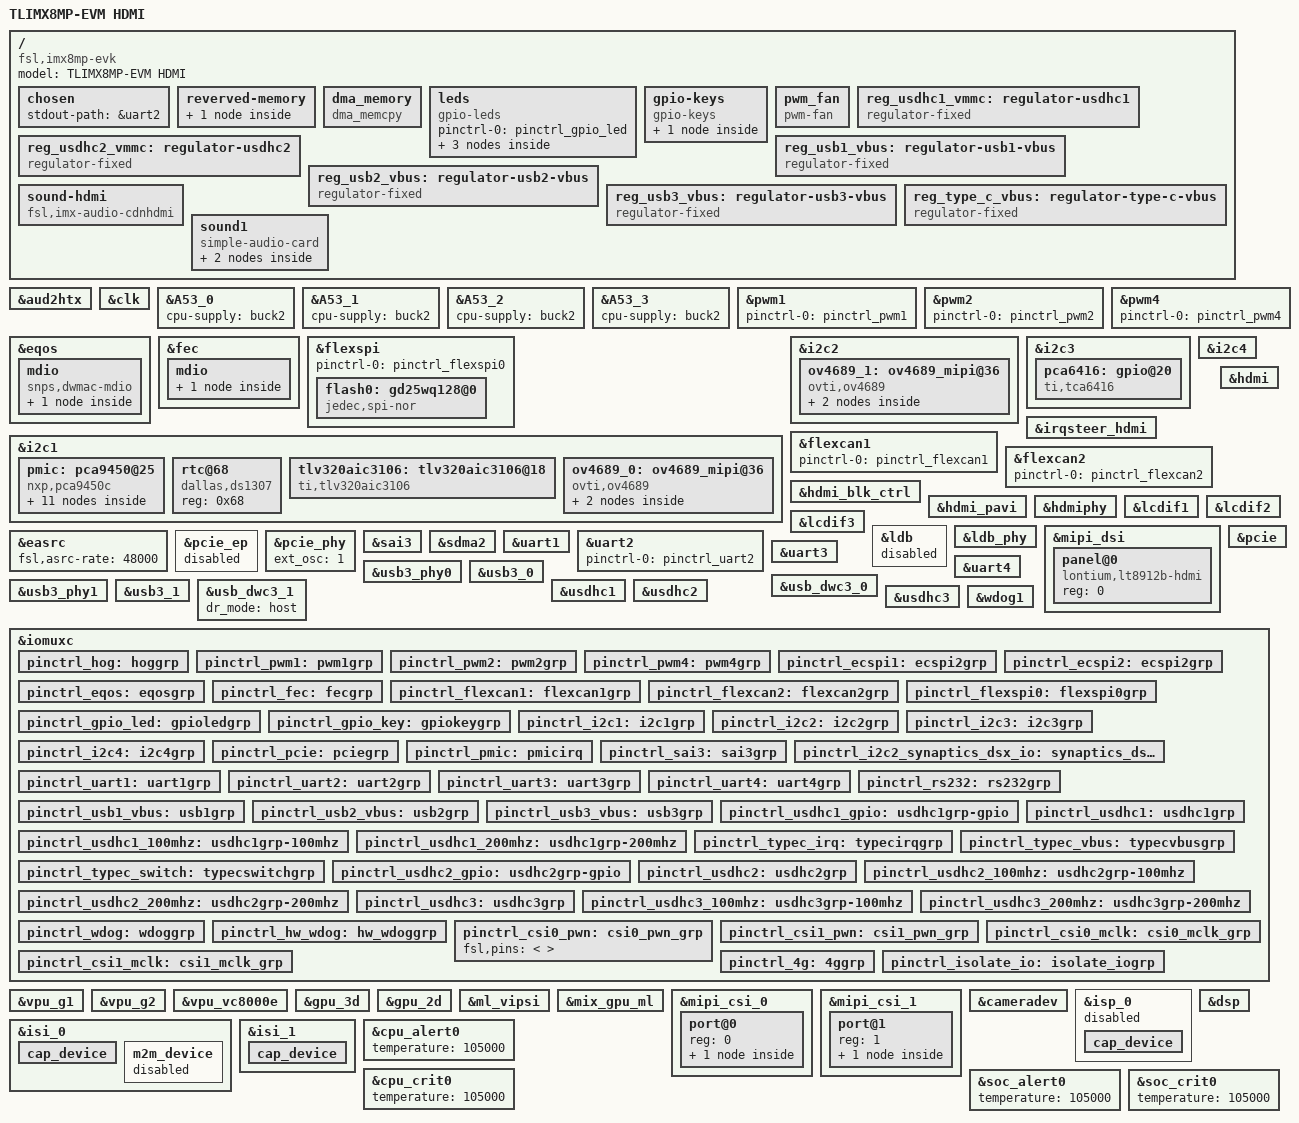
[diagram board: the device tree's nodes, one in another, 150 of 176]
/*
 * Copyright (C) 2015 GuangZhou Tronlong co., LTD - http://www.tronlong.com
 *
 * This program is free software; you can redistribute it and/or modify
 * it under the terms of the GNU General Public License version 2 as
 * published by the Free Software Foundation.
 */

/dts-v1/;

#include <dt-bindings/usb/pd.h>
#include "imx8mp.dtsi"

/{
	model = "TLIMX8MP-EVM HDMI";

	compatible = "fsl,imx8mp-evk", "fsl,imx8mp";

	chosen {
		stdout-path = &uart2;
	};

	reverved-memory {
		#address-cells = <2>;
		#size-cells = <2>;
		ranges;

		rpmsg_reserved: rpmsg@0x55800000 {
			no-map;
			reg = <0 0x55800000 0 0x800000>;
		};
	};
	
	dma_memory {
		status = "okay";
		compatible = "dma_memcpy";
	};

	leds {
		compatible = "gpio-leds";
		pinctrl-names = "default";
		pinctrl-0 = <&pinctrl_gpio_led>;

		led@0 {
			label = "heartbeat";
			gpios = <&gpio3 16 GPIO_ACTIVE_HIGH>;
			linux,default-trigger = "heartbeat";
			default-state = "off";
		};

		led@1 {
			label = "disk";
			gpios = <&gpio1 0 GPIO_ACTIVE_HIGH>;
			linux,default-trigger = "mmc2";
			default-state = "off";
		};

		led@2 {
			label = "user-led0";
			gpios = <&gpio1 5 GPIO_ACTIVE_HIGH>;
			default-state = "on";
		};
	};

	gpio-keys {
		compatible = "gpio-keys";
		#address-cells = <1>;
		#size-cells = <0>;
		autorepeat;

		pinctrl-names = "default";
		pinctrl-0 = <&pinctrl_gpio_key>;

		user_key@0 {
			label = "user-key0";
			gpios = <&gpio1 1 GPIO_ACTIVE_LOW>;
			linux,code = <KEY_PROG1>;
			debounce-interval = <0>;
		};
	};

	pwm_fan: pwm_fan {
		compatible = "pwm-fan";
		cooling-min-state = <0>;
		cooling-max-state = <3>;
		#cooling-cells = <2>;
		pwms = <&pwm4 0 50000 0>;
		cooling-levels = <0 102 170 230>;
	};

	reg_usdhc1_vmmc: regulator-usdhc1 {
		compatible = "regulator-fixed";
		regulator-name = "VSD_3V3";
		regulator-min-microvolt = <3300000>;
		regulator-max-microvolt = <3300000>;
		gpio = <&gpio2 10 GPIO_ACTIVE_HIGH>;
		enable-active-high;
		startup-delay-us = <100>;
		off-on-delay-us = <12000>;
	};

	reg_usdhc2_vmmc: regulator-usdhc2 {
		compatible = "regulator-fixed";
		regulator-name = "VSD_3V3";
		regulator-min-microvolt = <3300000>;
		regulator-max-microvolt = <3300000>;
		gpio = <&gpio2 19 GPIO_ACTIVE_HIGH>;
		enable-active-high;
		startup-delay-us = <100>;
		off-on-delay-us = <12000>;
	};

	reg_usb1_vbus: regulator-usb1-vbus {
		compatible = "regulator-fixed";
		regulator-name = "usb1-vbus";
		pinctrl-names = "default";
		pinctrl-0 = <&pinctrl_usb1_vbus>;
		regulator-min-microvolt = <3300000>;
		regulator-max-microvolt = <3300000>;
		gpio = <&gpio4 28 GPIO_ACTIVE_HIGH>;
		enable-active-high;
		regulator-always-on;
	};

	reg_usb2_vbus: regulator-usb2-vbus {
		compatible = "regulator-fixed";
		regulator-name = "usb2-vbus";
		pinctrl-names = "default";
		pinctrl-0 = <&pinctrl_usb2_vbus>;
		regulator-min-microvolt = <3300000>;
		regulator-max-microvolt = <3300000>;
		gpio = <&gpio1 6 GPIO_ACTIVE_HIGH>;
		enable-active-high;
		regulator-always-on;
	};

	reg_usb3_vbus: regulator-usb3-vbus {
		compatible = "regulator-fixed";
		regulator-name = "usb3-vbus";
		pinctrl-names = "default";
		pinctrl-0 = <&pinctrl_usb3_vbus>;
		regulator-min-microvolt = <3300000>;
		regulator-max-microvolt = <3300000>;
		gpio = <&gpio5 5 GPIO_ACTIVE_HIGH>;
		enable-active-high;
		regulator-always-on;
	};

	reg_type_c_vbus: regulator-type-c-vbus {
		compatible = "regulator-fixed";
		regulator-name = "type-c-vbus";
		pinctrl-names = "default";
		pinctrl-0 = <&pinctrl_typec_vbus>;
		regulator-min-microvolt = <3300000>;
		regulator-max-microvolt = <3300000>;
		gpio = <&gpio4 21 GPIO_ACTIVE_HIGH>;
		enable-active-high;
		regulator-always-on;
	};

	sound-hdmi {
		compatible = "fsl,imx-audio-cdnhdmi";
		model = "audio-hdmi";
		audio-cpu = <&aud2htx>;
		hdmi-out;
		constraint-rate = <44100>,
				<88200>,
				<176400>,
				<32000>,
				<48000>,
				<96000>,
				<192000>;
		status = "okay";
	};


	sound1: sound1 {
		compatible = "simple-audio-card";
		simple-audio-card,name = "TLV320AIC3x-Card";
		simple-audio-card,widgets =
			"Line", "Line In Jack",
			"Line", "Line Out Jack";
		simple-audio-card,routing =
			"LINE1L", "Line In Jack",
			"LINE1R", "Line In Jack",
			"Line Out Jack", "LLOUT",
			"Line Out Jack", "RLOUT";

		simple-audio-card,format = "dsp_b";
		simple-audio-card,bitclock-master = <&sound1_master>;
		simple-audio-card,frame-master = <&sound1_master>;
		simple-audio-card,bitclock-inversion;

		cpudai: simple-audio-card,cpu {
			sound-dai = <&sai3 0>;
		};

		sound1_master: simple-audio-card,codec {
			sound-dai = <&tlv320aic3106>;
			clocks = <&audio_blk_ctrl IMX8MP_CLK_AUDIO_BLK_CTRL_SAI3_MCLK1>;
			system-clock-frequency = <24576000>;
			system-clock-direction-out;
		};
	};

};

&aud2htx {
	status = "okay";
};

&clk {
	init-on-array = <IMX8MP_CLK_HSIO_ROOT IMX8MP_CLK_IPP_DO_CLKO1 IMX8MP_CLK_IPP_DO_CLKO2>;
};

&A53_0 {
	cpu-supply = <&buck2>;
};
&A53_1 {
	cpu-supply = <&buck2>;
};
&A53_2 {
	cpu-supply = <&buck2>;
};
&A53_3 {
	cpu-supply = <&buck2>;
};

&pwm1 {
	pinctrl-names = "default";
	pinctrl-0 = <&pinctrl_pwm1>;
	status = "okay";
};

&pwm2 {
	pinctrl-names = "default";
	pinctrl-0 = <&pinctrl_pwm2>;
	status = "okay";
};

&pwm4 {
	pinctrl-names = "default";
	pinctrl-0 = <&pinctrl_pwm4>;
	status = "okay";
};

/*
&ecspi2 {
	#address-cells = <1>;
	#size-cells = <0>;
	fsl,spi-num-chipselects = <1>;
	pinctrl-names = "default";
	pinctrl-0 = <&pinctrl_ecspi2 &pinctrl_ecspi2_cs>;
	cs-gpios = <&gpio5 13 GPIO_ACTIVE_LOW>;
	status = "okay";

	spidev1: spi@0 {
		reg = <0>;
		compatible = "rohm,dh2228fv";
		spi-max-frequency = <500000>;
	};
};
*/

&eqos {
	pinctrl-names = "default";
	pinctrl-0 = <&pinctrl_eqos>;
	phy-mode = "rgmii-id";
	phy-handle = <&ethphy0>;
	status = "okay";

	phy-reset-gpios = <&gpio4 0 GPIO_ACTIVE_LOW>;
	phy-reset-duration = <50>;
	phy-reset-post-delay = <50>;

	mdio {
		compatible = "snps,dwmac-mdio";
		#address-cells = <1>;
		#size-cells = <0>;

		ethphy0: ethernet-phy@1 {
			compatible = "ethernet-phy-ieee802.3-c22";
			reg = <1>;
			eee-broken-1000t;
			phy-tx-delay = <0x08>;	/* yt8521sh tx delay: 0~0xf, 150ps each step */
			phy-rx-delay = <0x00>;	/* yt8521sh rx delay: 0~0xf, 150ps each step */
		};
	};
};

&fec {
	pinctrl-names = "default";
	pinctrl-0 = <&pinctrl_fec>;
	phy-mode = "rgmii-id";
	phy-handle = <&ethphy1>;
	fsl,magic-packet;
	status = "okay";

	phy-reset-gpios = <&gpio4 24 GPIO_ACTIVE_LOW>;
	phy-reset-duration = <50>;
	phy-reset-post-delay = <50>;

	mdio {
		#address-cells = <1>;
		#size-cells = <0>;

		ethphy1: ethernet-phy@1 {
			compatible = "ethernet-phy-ieee802.3-c22";
			reg = <0>;
			eee-broken-1000t;
			phy-tx-delay = <0x01>;	/* yt8521sh tx delay: 0~0xf, 150ps each step */
			phy-rx-delay = <0x00>;	/* yt8521sh rx delay: 0~0xf, 150ps each step */
		};
	};
};

&flexspi {
	pinctrl-names = "default";
	pinctrl-0 = <&pinctrl_flexspi0>;
	status = "okay";

	flash0: gd25wq128@0 {
		reg = <0>;
		#address-cells = <1>;
		#size-cells = <1>;
		compatible = "jedec,spi-nor";
		spi-max-frequency = <80000000>;
		spi-tx-bus-width = <4>;
		spi-rx-bus-width = <4>;
	};
};

&i2c1 {
	clock-frequency = <100000>;
	pinctrl-names = "default";
	pinctrl-0 = <&pinctrl_i2c1>;
	status = "okay";

	pmic: pca9450@25 {
		reg = <0x25>;
		compatible = "nxp,pca9450c";
		pinctrl-names = "default";
		pinctrl-0 = <&pinctrl_pmic>;
		interrupt-parent = <&gpio1>;
		interrupts = <3 IRQ_TYPE_LEVEL_LOW>;

		regulators {
			buck1: BUCK1 {
                                regulator-name = "BUCK1";
                                regulator-min-microvolt = <600000>;
                                regulator-max-microvolt = <2187500>;
                                regulator-boot-on;
                                regulator-always-on;
                                regulator-ramp-delay = <3125>;
                        };

			buck2: BUCK2 {
                                regulator-name = "BUCK2";
                                regulator-min-microvolt = <600000>;
                                regulator-max-microvolt = <2187500>;
                                regulator-boot-on;
                                regulator-always-on;
                                regulator-ramp-delay = <3125>;
                                nxp,dvs-run-voltage = <950000>;
                                nxp,dvs-standby-voltage = <850000>;
                        };

                        buck4: BUCK4 {
                                regulator-name = "BUCK4";
                                regulator-min-microvolt = <600000>;
                                regulator-max-microvolt = <3400000>;
                                regulator-boot-on;
                                regulator-always-on;
                        };

                        buck5: BUCK5 {
                                regulator-name = "BUCK5";
                                regulator-min-microvolt = <600000>;
                                regulator-max-microvolt = <3400000>;
                                regulator-boot-on;
                                regulator-always-on;
                        };

                        buck6: BUCK6 {
                                regulator-name = "BUCK6";
                                regulator-min-microvolt = <600000>;
                                regulator-max-microvolt = <3400000>;
                                regulator-boot-on;
                                regulator-always-on;
                        };

                        ldo1: LDO1 {
                                regulator-name = "LDO1";
                                regulator-min-microvolt = <1600000>;
                                regulator-max-microvolt = <3300000>;
                                regulator-boot-on;
                                regulator-always-on;
                        };

                        ldo2: LDO2 {
                                regulator-name = "LDO2";
                                regulator-min-microvolt = <800000>;
                                regulator-max-microvolt = <1150000>;
                                regulator-boot-on;
                                regulator-always-on;
                        };

                        ldo3: LDO3 {
                                regulator-name = "LDO3";
                                regulator-min-microvolt = <800000>;
                                regulator-max-microvolt = <3300000>;
                                regulator-boot-on;
                                regulator-always-on;
                        };

                        ldo4: LDO4 {
                                regulator-name = "LDO4";
                                regulator-min-microvolt = <800000>;
                                regulator-max-microvolt = <3300000>;
                                regulator-boot-on;
                                regulator-always-on;
                        };

                        ldo5: LDO5 {
                                regulator-name = "LDO5";
                                regulator-min-microvolt = <1800000>;
                                regulator-max-microvolt = <3300000>;
                                regulator-boot-on;
                                regulator-always-on;
			};
		};
	};

	rtc@68 {
		compatible = "dallas,ds1307";
		reg = <0x68>;
	};

	tlv320aic3106: tlv320aic3106@18 {
		#sound-dai-cells = <0>;
		compatible = "ti,tlv320aic3106";
		reg = <0x18>;
		status = "okay";
		ai3x-micbias-vg = <2>; /* MICBIAS output is powered to 2.0V */
	};

        ov4689_0: ov4689_mipi@36 {
                compatible = "ovti,ov4689";
                reg = <0x36>;
                pinctrl-names = "default";
                pinctrl-0 = <&pinctrl_csi0_pwn>, <&pinctrl_csi0_mclk>;
                clocks = <&clk IMX8MP_CLK_IPP_DO_CLKO2>;
                clock-names = "xclk";
                assigned-clocks = <&clk IMX8MP_CLK_IPP_DO_CLKO2>;
                assigned-clock-parents = <&clk IMX8MP_CLK_24M>;
                assigned-clock-rates = <24000000>;
                csi_id = <0>;
                mclk = <24000000>;
                mclk_source = <0>;
                mipi_csi;
                status = "okay";

                port {
                        ov4689_mipi_0_ep: endpoint {
                                remote-endpoint = <&mipi_csi0_ep>;
				data-lanes = <1 2 3 4>;
                                clock-lanes = <0>;
                        };
                };
        };

};

&i2c2 {
	clock-frequency = <100000>;
	pinctrl-names = "default";
	pinctrl-0 = <&pinctrl_i2c2>;
	status = "okay";

        ov4689_1: ov4689_mipi@36 {
                compatible = "ovti,ov4689";
                reg = <0x36>;
                pinctrl-names = "default";
                pinctrl-0 = <&pinctrl_csi1_pwn>, <&pinctrl_csi1_mclk>;
                clocks = <&clk IMX8MP_CLK_IPP_DO_CLKO2>;
                clock-names = "xclk";
                assigned-clocks = <&clk IMX8MP_CLK_IPP_DO_CLKO2>;
                assigned-clock-parents = <&clk IMX8MP_CLK_24M>;
                assigned-clock-rates = <24000000>;
                csi_id = <1>;
                mclk = <24000000>;
                mclk_source = <0>;
                mipi_csi;
                status = "okay";

                port {
                        ov4689_mipi_1_ep: endpoint {
                                remote-endpoint = <&mipi_csi1_ep>;
                                data-lanes = <1 2 3 4>;
                                clock-lanes = <0>;
                        };
                };
        };
};

&i2c3 {
	clock-frequency = <100000>;
	pinctrl-names = "default";
	pinctrl-0 = <&pinctrl_i2c3>;
	status = "okay";

	pca6416: gpio@20 {
		compatible = "ti,tca6416";
		reg = <0x20>;
		gpio-controller;
		#gpio-cells = <2>;
	};
};


&i2c4 {
	clock-frequency = <100000>;
	pinctrl-names = "default";
	pinctrl-0 = <&pinctrl_i2c4>;
	status = "okay";
};

&irqsteer_hdmi {
	status = "okay";
};

&flexcan1 {
	pinctrl-names = "default";
	pinctrl-0 = <&pinctrl_flexcan1>;
	status = "okay";
};

/* can2 pin conflict with pdm: gpio low select pdm, gpio high select can2 */
&flexcan2 {
	pinctrl-names = "default";
	pinctrl-0 = <&pinctrl_flexcan2>;
	status = "okay";
};

&irqsteer_hdmi {
	status = "okay";
};

&hdmi_blk_ctrl {
	status = "okay";
};

&hdmi_pavi {
	status = "okay";
};

&hdmi {
	status = "okay";
};

&hdmiphy {
	status = "okay";
};

&lcdif1 {
	status = "okay";
};

&lcdif2 {
	status = "okay";
};

&lcdif3 {
	status = "okay";

	thres-low  = <1 2>;             /* (FIFO * 1 / 2) */
	thres-high = <3 4>;             /* (FIFO * 3 / 4) */
};

&ldb {
	status = "disabled";
};

&ldb_phy {
	status = "okay";
};

&mipi_dsi {
	status = "okay";

	panel@0 {
		compatible = "lontium,lt8912b-hdmi";
		reg = <0>;
		status = "okay";
	};
};

&easrc {
	fsl,asrc-rate  = <48000>;
	status = "okay";
};


&pcie {
	pinctrl-names = "default";
	pinctrl-0 = <&pinctrl_pcie>, <&pinctrl_4g>;
	disable-gpio = <&gpio4 23 GPIO_ACTIVE_LOW>;
	reset-gpio = <&gpio2 11 GPIO_ACTIVE_LOW>;
	rm500q-reset-gpio = <&gpio4 3 GPIO_ACTIVE_HIGH>;
	rm500q-power-off = <&gpio4 25 GPIO_ACTIVE_LOW>;
	pcie-clkreq = <&gpio4 29 GPIO_ACTIVE_LOW>;
	ext_osc = <1>;
	clocks = <&clk IMX8MP_CLK_HSIO_ROOT>,
		 <&clk IMX8MP_CLK_PCIE_AUX>,
		 <&clk IMX8MP_CLK_HSIO_AXI>,
		 <&clk IMX8MP_CLK_PCIE_ROOT>;
	clock-names = "pcie", "pcie_aux", "pcie_phy", "pcie_bus";
	assigned-clocks = <&clk IMX8MP_CLK_HSIO_AXI>,
			  <&clk IMX8MP_CLK_PCIE_AUX>;
	assigned-clock-rates = <500000000>, <10000000>;
	assigned-clock-parents = <&clk IMX8MP_SYS_PLL2_500M>,
				 <&clk IMX8MP_SYS_PLL2_50M>;
	status = "okay";
};

&pcie_ep {
	pinctrl-names = "default";
	pinctrl-0 = <&pinctrl_pcie>;
	ext_osc = <1>;
	clocks = <&clk IMX8MP_CLK_HSIO_ROOT>,
		 <&clk IMX8MP_CLK_PCIE_AUX>,
		 <&clk IMX8MP_CLK_HSIO_AXI>,
		 <&clk IMX8MP_CLK_PCIE_ROOT>;
	clock-names = "pcie", "pcie_aux", "pcie_phy", "pcie_bus";
	assigned-clocks = <&clk IMX8MP_CLK_HSIO_AXI>,
			  <&clk IMX8MP_CLK_PCIE_AUX>;
	assigned-clock-rates = <500000000>, <10000000>;
	assigned-clock-parents = <&clk IMX8MP_SYS_PLL2_500M>,
				 <&clk IMX8MP_SYS_PLL2_50M>;
	status = "disabled";
};

&pcie_phy {
	ext_osc = <1>;
	status = "okay";
};


&sai3 {
	#sound-dai-cells = <0>;
	pinctrl-names = "default";
	pinctrl-0 = <&pinctrl_sai3>;
	assigned-clocks = <&clk IMX8MP_CLK_SAI3>;
	assigned-clock-parents = <&clk IMX8MP_AUDIO_PLL1_OUT>;
	assigned-clock-rates = <24576000>;
	clocks = <&audio_blk_ctrl IMX8MP_CLK_AUDIO_BLK_CTRL_SAI3_IPG>, <&clk IMX8MP_CLK_DUMMY>,
		 <&audio_blk_ctrl IMX8MP_CLK_AUDIO_BLK_CTRL_SAI3_MCLK1>, <&clk IMX8MP_CLK_DUMMY>,
		 <&clk IMX8MP_CLK_DUMMY>;
	clock-names = "bus", "mclk0", "mclk1", "mclk2", "mclk3";
	fsl,sai-mclk-direction-output;
	status = "okay";
};

&sdma2 {
	status = "okay";
};

&uart1 {
	pinctrl-names = "default";
	pinctrl-0 = <&pinctrl_uart1>;
	assigned-clocks = <&clk IMX8MP_CLK_UART1>;
	assigned-clock-parents = <&clk IMX8MP_SYS_PLL1_80M>;
	fsl,uart-has-rtscts;
	status = "okay";
};

&uart2 {
	/* console */
	pinctrl-names = "default";
	pinctrl-0 = <&pinctrl_uart2>;
	status = "okay";
};

&uart3 {
	pinctrl-names = "default";
	pinctrl-0 = <&pinctrl_uart3>;
	assigned-clocks = <&clk IMX8MP_CLK_UART3>;
	assigned-clock-parents = <&clk IMX8MP_SYS_PLL1_80M>;
	status = "okay";
};

&uart4 {
	pinctrl-names = "default";
	pinctrl-0 = <&pinctrl_rs232>;
	assigned-clocks = <&clk IMX8MP_CLK_UART3>;
	assigned-clock-parents = <&clk IMX8MP_SYS_PLL1_80M>;
	status = "okay";
};

&usb3_phy0 {
	fsl,phy-tx-vref-tune = <0xe>;
	fsl,phy-tx-preemp-amp-tune = <3>;
	fsl,phy-tx-vboost-level = <5>;
	fsl,phy-comp-dis-tune = <7>;
	fsl,pcs-tx-deemph-3p5db = <0x21>;
	fsl,phy-pcs-tx-swing-full = <0x7f>;
	status = "okay";
};

&usb3_0 {
	status = "okay";
};

&usb_dwc3_0 {
	hnp-disable;
	srp-disable;
	adp-disable;
	usb-role-switch;
	role-switch-default-mode = "host";
	status = "okay";
};

&usb3_phy1 {
	fsl,phy-tx-preemp-amp-tune = <3>;
	fsl,phy-tx-vref-tune = <0xb>;
	status = "okay";
};

&usb3_1 {
	status = "okay";
};

&usb_dwc3_1 {
	dr_mode = "host";
	status = "okay";
};

&usdhc1 {
	pinctrl-names = "default", "state_100mhz", "state_200mhz";
	pinctrl-0 = <&pinctrl_usdhc1>, <&pinctrl_usdhc1_gpio>;
	pinctrl-1 = <&pinctrl_usdhc1_100mhz>, <&pinctrl_usdhc1_gpio>;
	pinctrl-2 = <&pinctrl_usdhc1_200mhz>, <&pinctrl_usdhc1_gpio>;
	// cd-gpios = <&gpio2 12 GPIO_ACTIVE_LOW>;
	vmmc-supply = <&reg_usdhc1_vmmc>;
	bus-width = <8>;
	status = "okay";
};

&usdhc2 {
	pinctrl-names = "default", "state_100mhz", "state_200mhz";
	pinctrl-0 = <&pinctrl_usdhc2>, <&pinctrl_usdhc2_gpio>;
	pinctrl-1 = <&pinctrl_usdhc2_100mhz>, <&pinctrl_usdhc2_gpio>;
	pinctrl-2 = <&pinctrl_usdhc2_200mhz>, <&pinctrl_usdhc2_gpio>;
	cd-gpios = <&gpio2 12 GPIO_ACTIVE_LOW>;
	vmmc-supply = <&reg_usdhc2_vmmc>;
	bus-width = <4>;
	status = "okay";
};

&usdhc3 {
	pinctrl-names = "default", "state_100mhz", "state_200mhz";
	pinctrl-0 = <&pinctrl_usdhc3>;
	pinctrl-1 = <&pinctrl_usdhc3_100mhz>;
	pinctrl-2 = <&pinctrl_usdhc3_200mhz>;
	bus-width = <8>;
	non-removable;
	status = "okay";
};


&wdog1 {
	pinctrl-names = "default";
	pinctrl-0 = <&pinctrl_wdog>;
	fsl,ext-reset-output;
	status = "okay";
};

&iomuxc {
	pinctrl-names = "default";
	pinctrl-0 = <&pinctrl_hog &pinctrl_hw_wdog &pinctrl_isolate_io>;

	pinctrl_hog: hoggrp {
		fsl,pins = <
			MX8MP_IOMUXC_HDMI_DDC_SCL__HDMIMIX_HDMI_SCL	0x400001c3
			MX8MP_IOMUXC_HDMI_DDC_SDA__HDMIMIX_HDMI_SDA	0x400001c3
			MX8MP_IOMUXC_HDMI_HPD__HDMIMIX_HDMI_HPD		0x40000019
			MX8MP_IOMUXC_HDMI_CEC__HDMIMIX_HDMI_CEC		0x40000019
		>;
	};

	pinctrl_pwm1: pwm1grp {
		fsl,pins = <
			MX8MP_IOMUXC_GPIO1_IO08__PWM1_OUT	0x116
		>;
	};

	pinctrl_pwm2: pwm2grp {
		fsl,pins = <
			MX8MP_IOMUXC_GPIO1_IO09__PWM2_OUT	0x116
		>;
	};

	pinctrl_pwm4: pwm4grp {
		fsl,pins = <
			MX8MP_IOMUXC_SAI5_RXFS__PWM4_OUT	0x116
		>;
	};


	pinctrl_ecspi1: ecspi2grp {
		fsl,pins = <
			MX8MP_IOMUXC_ECSPI1_SCLK__GPIO5_IO06		0x00000106
			MX8MP_IOMUXC_ECSPI1_MOSI__GPIO5_IO07		0x00000106
			MX8MP_IOMUXC_ECSPI1_MISO__GPIO5_IO08		0x00000106
			MX8MP_IOMUXC_ECSPI1_SS0__GPIO5_IO09			0x00000106
		>;
	};


	pinctrl_ecspi2: ecspi2grp {
		fsl,pins = <
			MX8MP_IOMUXC_ECSPI2_SCLK__GPIO5_IO10		0x00000106
			MX8MP_IOMUXC_ECSPI2_MOSI__GPIO5_IO11		0x00000106
			MX8MP_IOMUXC_ECSPI2_MISO__GPIO5_IO12		0x00000106
			MX8MP_IOMUXC_ECSPI2_SS0__GPIO5_IO13			0x00000106
		>;
	};


	pinctrl_eqos: eqosgrp {
		fsl,pins = <
			MX8MP_IOMUXC_ENET_MDC__ENET_QOS_MDC	0x3
			MX8MP_IOMUXC_ENET_MDIO__ENET_QOS_MDIO	0x3
			MX8MP_IOMUXC_ENET_RD0__ENET_QOS_RGMII_RD0	0x91
			MX8MP_IOMUXC_ENET_RD1__ENET_QOS_RGMII_RD1	0x91
			MX8MP_IOMUXC_ENET_RD2__ENET_QOS_RGMII_RD2	0x91
			MX8MP_IOMUXC_ENET_RD3__ENET_QOS_RGMII_RD3	0x91
			MX8MP_IOMUXC_ENET_RXC__CCM_ENET_QOS_CLOCK_GENERATE_RX_CLK	0x91
			MX8MP_IOMUXC_ENET_RX_CTL__ENET_QOS_RGMII_RX_CTL	0x91
			MX8MP_IOMUXC_ENET_TD0__ENET_QOS_RGMII_TD0		0x1f
			MX8MP_IOMUXC_ENET_TD1__ENET_QOS_RGMII_TD1		0x1f
			MX8MP_IOMUXC_ENET_TD2__ENET_QOS_RGMII_TD2		0x1f
			MX8MP_IOMUXC_ENET_TD3__ENET_QOS_RGMII_TD3		0x1f
			MX8MP_IOMUXC_ENET_TX_CTL__ENET_QOS_RGMII_TX_CTL	0x1f
			MX8MP_IOMUXC_ENET_TXC__CCM_ENET_QOS_CLOCK_GENERATE_TX_CLK	0x1f
		>;
	};

	pinctrl_fec: fecgrp {
		fsl,pins = <
			MX8MP_IOMUXC_SAI1_RXD2__ENET1_MDC		0x3
			MX8MP_IOMUXC_SAI1_RXD3__ENET1_MDIO		0x3
			MX8MP_IOMUXC_SAI1_RXD4__ENET1_RGMII_RD0		0x91
			MX8MP_IOMUXC_SAI1_RXD5__ENET1_RGMII_RD1		0x91
			MX8MP_IOMUXC_SAI1_RXD6__ENET1_RGMII_RD2		0x91
			MX8MP_IOMUXC_SAI1_RXD7__ENET1_RGMII_RD3		0x91
			MX8MP_IOMUXC_SAI1_TXC__ENET1_RGMII_RXC		0x91
			MX8MP_IOMUXC_SAI1_TXFS__ENET1_RGMII_RX_CTL	0x91
			MX8MP_IOMUXC_SAI1_TXD0__ENET1_RGMII_TD0		0x1f
			MX8MP_IOMUXC_SAI1_TXD1__ENET1_RGMII_TD1		0x1f
			MX8MP_IOMUXC_SAI1_TXD2__ENET1_RGMII_TD2		0x1f
			MX8MP_IOMUXC_SAI1_TXD3__ENET1_RGMII_TD3		0x1f
			MX8MP_IOMUXC_SAI1_TXD4__ENET1_RGMII_TX_CTL	0x1f
			MX8MP_IOMUXC_SAI1_TXD5__ENET1_RGMII_TXC		0x1f
		>;
	};

	pinctrl_flexcan1: flexcan1grp {
		fsl,pins = <
			MX8MP_IOMUXC_SAI5_RXD2__CAN1_RX          0x154
			MX8MP_IOMUXC_SAI5_RXD1__CAN1_TX          0x154
		>;
	};

	pinctrl_flexcan2: flexcan2grp {
		fsl,pins = <
			MX8MP_IOMUXC_SAI5_MCLK__CAN2_RX		0x154
			MX8MP_IOMUXC_SAI5_RXD3__CAN2_TX		0x154
		>;
	};

	pinctrl_flexspi0: flexspi0grp {
		fsl,pins = <
			MX8MP_IOMUXC_NAND_ALE__FLEXSPI_A_SCLK		0x1c2
			MX8MP_IOMUXC_NAND_CE0_B__FLEXSPI_A_SS0_B	0x82
			MX8MP_IOMUXC_NAND_DATA00__FLEXSPI_A_DATA00	0x82
			MX8MP_IOMUXC_NAND_DATA01__FLEXSPI_A_DATA01	0x82
			MX8MP_IOMUXC_NAND_DATA02__FLEXSPI_A_DATA02	0x82
			MX8MP_IOMUXC_NAND_DATA03__FLEXSPI_A_DATA03	0x82
		>;
	};

	pinctrl_gpio_led: gpioledgrp {
		fsl,pins = <
			MX8MP_IOMUXC_GPIO1_IO00__GPIO1_IO00	0x00000106
			MX8MP_IOMUXC_GPIO1_IO05__GPIO1_IO05	0x00000146
			MX8MP_IOMUXC_NAND_READY_B__GPIO3_IO16	0x00000106
		>;
	};

	pinctrl_gpio_key: gpiokeygrp {
		fsl,pins = <
			MX8MP_IOMUXC_GPIO1_IO01__GPIO1_IO01	0x00000106
		>;
	};

	pinctrl_i2c1: i2c1grp {
		fsl,pins = <
			MX8MP_IOMUXC_I2C1_SCL__I2C1_SCL		0x400001c3
			MX8MP_IOMUXC_I2C1_SDA__I2C1_SDA		0x400001c3
		>;
	};

	pinctrl_i2c2: i2c2grp {
		fsl,pins = <
			MX8MP_IOMUXC_I2C2_SCL__I2C2_SCL			0x400001c3
			MX8MP_IOMUXC_I2C2_SDA__I2C2_SDA			0x400001c3
		>;
	};

	pinctrl_i2c3: i2c3grp {
		fsl,pins = <
			MX8MP_IOMUXC_I2C3_SCL__I2C3_SCL			0x400001c3
			MX8MP_IOMUXC_I2C3_SDA__I2C3_SDA			0x400001c3
		>;
	};

	pinctrl_i2c4: i2c4grp {
		fsl,pins = <
			MX8MP_IOMUXC_I2C4_SCL__I2C4_SCL			0x400001c3
			MX8MP_IOMUXC_I2C4_SDA__I2C4_SDA			0x400001c3
		>;
	};

	pinctrl_pcie: pciegrp {
		fsl,pins = <
			MX8MP_IOMUXC_SD1_STROBE__GPIO2_IO11		0x61 /* open drain, pull up */
			MX8MP_IOMUXC_SAI3_RXC__GPIO4_IO29		0x46
			MX8MP_IOMUXC_SAI2_TXC__GPIO4_IO25		0x41
			MX8MP_IOMUXC_SAI2_RXD0__GPIO4_IO23		0x46
		>;
	};

	pinctrl_pmic: pmicirq {
		fsl,pins = <
			MX8MP_IOMUXC_GPIO1_IO03__GPIO1_IO03	0x41
		>;
	};

	pinctrl_sai3: sai3grp {
		fsl,pins = <
			MX8MP_IOMUXC_SAI3_TXFS__AUDIOMIX_SAI3_TX_SYNC	0xd6
			MX8MP_IOMUXC_SAI3_TXC__AUDIOMIX_SAI3_TX_BCLK	0xd6
			MX8MP_IOMUXC_SAI3_RXD__AUDIOMIX_SAI3_RX_DATA00	0xd6
			MX8MP_IOMUXC_SAI3_TXD__AUDIOMIX_SAI3_TX_DATA00	0xd6
			MX8MP_IOMUXC_SAI3_MCLK__AUDIOMIX_SAI3_MCLK	0xd6
		>;
	};

	pinctrl_i2c2_synaptics_dsx_io: synaptics_dsx_iogrp {
		fsl,pins = <
			MX8MP_IOMUXC_GPIO1_IO09__GPIO1_IO09		0x16
		>;
	};

	pinctrl_uart1: uart1grp {
		fsl,pins = <
			MX8MP_IOMUXC_UART1_TXD__UART1_DCE_TX	0x140
			MX8MP_IOMUXC_UART1_RXD__UART1_DCE_RX	0x140
		>;
	};

	pinctrl_uart2: uart2grp {
		fsl,pins = <
			MX8MP_IOMUXC_UART2_RXD__UART2_DCE_RX	0x49
			MX8MP_IOMUXC_UART2_TXD__UART2_DCE_TX	0x49
		>;
	};

	pinctrl_uart3: uart3grp {
		fsl,pins = <
			MX8MP_IOMUXC_UART3_TXD__UART3_DCE_TX		0x140
			MX8MP_IOMUXC_UART3_RXD__UART3_DCE_RX		0x140
		>;
	};

	pinctrl_uart4: uart4grp {
		fsl,pins = <
			MX8MP_IOMUXC_UART4_TXD__UART4_DCE_TX		0x140
			MX8MP_IOMUXC_UART4_RXD__UART4_DCE_RX		0x140
		>;
	};

	pinctrl_rs232: rs232grp {
		fsl,pins = <
			MX8MP_IOMUXC_UART4_TXD__UART4_DCE_TX		0x140
			MX8MP_IOMUXC_UART4_RXD__UART4_DCE_RX		0x140
		>;
	};

	pinctrl_usb1_vbus: usb1grp {
		fsl,pins = <
			MX8MP_IOMUXC_SAI3_RXFS__GPIO4_IO28	0x19
		>;
	};

	pinctrl_usb2_vbus: usb2grp {
		fsl,pins = <
			MX8MP_IOMUXC_GPIO1_IO06__GPIO1_IO06	0x19
		>;
	};

	pinctrl_usb3_vbus: usb3grp {
		fsl,pins = <
			MX8MP_IOMUXC_SPDIF_EXT_CLK__GPIO5_IO05	0x19
		>;
	};

	pinctrl_usdhc1_gpio: usdhc1grp-gpio {
		fsl,pins = <
			//MX8MP_IOMUXC_SD2_CD_B__GPIO2_IO12 	0x1c4
			MX8MP_IOMUXC_SD1_RESET_B__GPIO2_IO10	0x41
		>;
	};

	pinctrl_usdhc1: usdhc1grp {
		fsl,pins = <
			MX8MP_IOMUXC_SD1_CLK__USDHC1_CLK	0x190
			MX8MP_IOMUXC_SD1_CMD__USDHC1_CMD	0x1d0
			MX8MP_IOMUXC_SD1_DATA0__USDHC1_DATA0	0x1d0
			MX8MP_IOMUXC_SD1_DATA1__USDHC1_DATA1	0x1d0
			MX8MP_IOMUXC_SD1_DATA2__USDHC1_DATA2	0x1d0
			MX8MP_IOMUXC_SD1_DATA3__USDHC1_DATA3	0x1d0
			MX8MP_IOMUXC_SD1_DATA4__USDHC1_DATA4	0x1d0
			MX8MP_IOMUXC_SD1_DATA5__USDHC1_DATA5	0x1d0
			MX8MP_IOMUXC_SD1_DATA6__USDHC1_DATA6	0x1d0
			MX8MP_IOMUXC_SD1_DATA7__USDHC1_DATA7	0x1d0
			//MX8MP_IOMUXC_GPIO1_IO04__USDHC2_VSELECT	0xc1
			MX8MP_IOMUXC_SD1_STROBE__USDHC1_STROBE	0x196
		>;
	};

	pinctrl_usdhc1_100mhz: usdhc1grp-100mhz {
		fsl,pins = <
			MX8MP_IOMUXC_SD1_CLK__USDHC1_CLK	0x190
			MX8MP_IOMUXC_SD1_CMD__USDHC1_CMD	0x1d0
			MX8MP_IOMUXC_SD1_DATA0__USDHC1_DATA0	0x1d0
			MX8MP_IOMUXC_SD1_DATA1__USDHC1_DATA1	0x1d0
			MX8MP_IOMUXC_SD1_DATA2__USDHC1_DATA2	0x1d0
			MX8MP_IOMUXC_SD1_DATA3__USDHC1_DATA3	0x1d0
			MX8MP_IOMUXC_SD1_DATA4__USDHC1_DATA4	0x1d0
			MX8MP_IOMUXC_SD1_DATA5__USDHC1_DATA5	0x1d0
			MX8MP_IOMUXC_SD1_DATA6__USDHC1_DATA6	0x1d0
			MX8MP_IOMUXC_SD1_DATA7__USDHC1_DATA7	0x1d0
			//MX8MP_IOMUXC_GPIO1_IO04__USDHC2_VSELECT 0xc1
			MX8MP_IOMUXC_SD1_STROBE__USDHC1_STROBE	0x196
		>;
	};

	pinctrl_usdhc1_200mhz: usdhc1grp-200mhz {
		fsl,pins = <
			MX8MP_IOMUXC_SD1_CLK__USDHC1_CLK	0x190
			MX8MP_IOMUXC_SD1_CMD__USDHC1_CMD	0x1d0
			MX8MP_IOMUXC_SD1_DATA0__USDHC1_DATA0	0x1d0
			MX8MP_IOMUXC_SD1_DATA1__USDHC1_DATA1	0x1d0
			MX8MP_IOMUXC_SD1_DATA2__USDHC1_DATA2	0x1d0
			MX8MP_IOMUXC_SD1_DATA3__USDHC1_DATA3	0x1d0
			MX8MP_IOMUXC_SD1_DATA4__USDHC1_DATA4	0x1d0
			MX8MP_IOMUXC_SD1_DATA5__USDHC1_DATA5	0x1d0
			MX8MP_IOMUXC_SD1_DATA6__USDHC1_DATA6	0x1d0
			MX8MP_IOMUXC_SD1_DATA7__USDHC1_DATA7	0x1d0
			//MX8MP_IOMUXC_GPIO1_IO04__USDHC2_VSELECT 0xc1
			MX8MP_IOMUXC_SD1_STROBE__USDHC1_STROBE	0x196
		>;
	};

	pinctrl_typec_irq: typecirqgrp {
		fsl,pins = <
			MX8MP_IOMUXC_SAI2_RXC__GPIO4_IO22	0x00000146
		>;
	};

	pinctrl_typec_vbus: typecvbusgrp {
		fsl,pins = <
			MX8MP_IOMUXC_SAI2_RXFS__GPIO4_IO21	0x106
		>;
	};

	pinctrl_typec_switch: typecswitchgrp {
		fsl,pins = <
			MX8MP_IOMUXC_GPIO1_IO07__GPIO1_IO07	0x16
		>;
	};

	pinctrl_usdhc2_gpio: usdhc2grp-gpio {
		fsl,pins = <
			MX8MP_IOMUXC_SD2_CD_B__GPIO2_IO12 	0x1c4
			MX8MP_IOMUXC_SD2_RESET_B__GPIO2_IO19	0x41			
			MX8MP_IOMUXC_SD2_WP__USDHC2_WP		0x1c4
		>;
	};

	pinctrl_usdhc2: usdhc2grp {
		fsl,pins = <
			MX8MP_IOMUXC_SD2_CLK__USDHC2_CLK	0x190
			MX8MP_IOMUXC_SD2_CMD__USDHC2_CMD	0x1d0
			MX8MP_IOMUXC_SD2_DATA0__USDHC2_DATA0	0x1d0
			MX8MP_IOMUXC_SD2_DATA1__USDHC2_DATA1	0x1d0
			MX8MP_IOMUXC_SD2_DATA2__USDHC2_DATA2	0x1d0
			MX8MP_IOMUXC_SD2_DATA3__USDHC2_DATA3	0x1d0
			// MX8MP_IOMUXC_GPIO1_IO04__USDHC2_VSELECT	0xc1
		>;
	};

	pinctrl_usdhc2_100mhz: usdhc2grp-100mhz {
		fsl,pins = <
			MX8MP_IOMUXC_SD2_CLK__USDHC2_CLK	0x190
			MX8MP_IOMUXC_SD2_CMD__USDHC2_CMD	0x1d0
			MX8MP_IOMUXC_SD2_DATA0__USDHC2_DATA0	0x1d0
			MX8MP_IOMUXC_SD2_DATA1__USDHC2_DATA1	0x1d0
			MX8MP_IOMUXC_SD2_DATA2__USDHC2_DATA2	0x1d0
			MX8MP_IOMUXC_SD2_DATA3__USDHC2_DATA3	0x1d0
			// MX8MP_IOMUXC_GPIO1_IO04__USDHC2_VSELECT 0xc1
		>;
	};

	pinctrl_usdhc2_200mhz: usdhc2grp-200mhz {
		fsl,pins = <
			MX8MP_IOMUXC_SD2_CLK__USDHC2_CLK	0x190
			MX8MP_IOMUXC_SD2_CMD__USDHC2_CMD	0x1d0
			MX8MP_IOMUXC_SD2_DATA0__USDHC2_DATA0	0x1d0
			MX8MP_IOMUXC_SD2_DATA1__USDHC2_DATA1	0x1d0
			MX8MP_IOMUXC_SD2_DATA2__USDHC2_DATA2	0x1d0
			MX8MP_IOMUXC_SD2_DATA3__USDHC2_DATA3	0x1d0
			// MX8MP_IOMUXC_GPIO1_IO04__USDHC2_VSELECT 0xc1
		>;
	};

	pinctrl_usdhc3: usdhc3grp {
		fsl,pins = <
			MX8MP_IOMUXC_NAND_WE_B__USDHC3_CLK	0x196
			MX8MP_IOMUXC_NAND_WP_B__USDHC3_CMD	0x1d6
			MX8MP_IOMUXC_NAND_DATA04__USDHC3_DATA0	0x1d6
			MX8MP_IOMUXC_NAND_DATA05__USDHC3_DATA1	0x1d6
			MX8MP_IOMUXC_NAND_DATA06__USDHC3_DATA2	0x1d6
			MX8MP_IOMUXC_NAND_DATA07__USDHC3_DATA3	0x1d6
			MX8MP_IOMUXC_NAND_RE_B__USDHC3_DATA4	0x1d6
			MX8MP_IOMUXC_NAND_CE2_B__USDHC3_DATA5	0x1d6
			MX8MP_IOMUXC_NAND_CE3_B__USDHC3_DATA6	0x1d6
			MX8MP_IOMUXC_NAND_CLE__USDHC3_DATA7	0x1d6
			MX8MP_IOMUXC_NAND_CE1_B__USDHC3_STROBE	0x196
		>;
	};

	pinctrl_usdhc3_100mhz: usdhc3grp-100mhz {
		fsl,pins = <
			MX8MP_IOMUXC_NAND_WE_B__USDHC3_CLK	0x196
			MX8MP_IOMUXC_NAND_WP_B__USDHC3_CMD	0x1d6
			MX8MP_IOMUXC_NAND_DATA04__USDHC3_DATA0	0x1d6
			MX8MP_IOMUXC_NAND_DATA05__USDHC3_DATA1	0x1d6
			MX8MP_IOMUXC_NAND_DATA06__USDHC3_DATA2	0x1d6
			MX8MP_IOMUXC_NAND_DATA07__USDHC3_DATA3	0x1d6
			MX8MP_IOMUXC_NAND_RE_B__USDHC3_DATA4	0x1d6
			MX8MP_IOMUXC_NAND_CE2_B__USDHC3_DATA5	0x1d6
			MX8MP_IOMUXC_NAND_CE3_B__USDHC3_DATA6	0x1d6
			MX8MP_IOMUXC_NAND_CLE__USDHC3_DATA7	0x1d6
			MX8MP_IOMUXC_NAND_CE1_B__USDHC3_STROBE	0x196
		>;
	};

	pinctrl_usdhc3_200mhz: usdhc3grp-200mhz {
		fsl,pins = <
			MX8MP_IOMUXC_NAND_WE_B__USDHC3_CLK	0x196
			MX8MP_IOMUXC_NAND_WP_B__USDHC3_CMD	0x1d6
			MX8MP_IOMUXC_NAND_DATA04__USDHC3_DATA0	0x1d6
			MX8MP_IOMUXC_NAND_DATA05__USDHC3_DATA1	0x1d6
			MX8MP_IOMUXC_NAND_DATA06__USDHC3_DATA2	0x1d6
			MX8MP_IOMUXC_NAND_DATA07__USDHC3_DATA3	0x1d6
			MX8MP_IOMUXC_NAND_RE_B__USDHC3_DATA4	0x1d6
			MX8MP_IOMUXC_NAND_CE2_B__USDHC3_DATA5	0x1d6
			MX8MP_IOMUXC_NAND_CE3_B__USDHC3_DATA6	0x1d6
			MX8MP_IOMUXC_NAND_CLE__USDHC3_DATA7	0x1d6
			MX8MP_IOMUXC_NAND_CE1_B__USDHC3_STROBE	0x196
		>;
	};

	pinctrl_wdog: wdoggrp {
		fsl,pins = <
			MX8MP_IOMUXC_GPIO1_IO02__WDOG1_WDOG_B	0xc6
		>;
	};

	pinctrl_hw_wdog: hw_wdoggrp {
		fsl,pins = <
			MX8MP_IOMUXC_SD1_DATA6__GPIO2_IO08	0x00000106	/* WDOG_WDI  */
			MX8MP_IOMUXC_SD1_DATA7__GPIO2_IO09	0x00000106	/* WDOG_SET */
		>;
	};

	pinctrl_csi0_pwn: csi0_pwn_grp {
		fsl,pins = <
			// MX8MP_IOMUXC_SAI5_MCLK__GPIO3_IO25	0x19
		>;
	};

	pinctrl_csi1_pwn: csi1_pwn_grp {
		fsl,pins = <
			MX8MP_IOMUXC_SAI5_RXC__GPIO3_IO20	0x19
		>;
	};

	pinctrl_csi0_mclk: csi0_mclk_grp {
		fsl,pins = <
			MX8MP_IOMUXC_GPIO1_IO14__CCM_CLKO1	0x59
		>;
	};

	pinctrl_csi1_mclk: csi1_mclk_grp {
		fsl,pins = <
			MX8MP_IOMUXC_GPIO1_IO15__CCM_CLKO2	0x59
		>;
	};

	pinctrl_4g: 4ggrp {
		fsl,pins = <
			MX8MP_IOMUXC_SAI1_RXD1__GPIO4_IO03	0x00000146	/* RST */
		>;
	};

	pinctrl_isolate_io: isolate_iogrp {
		fsl,pins = <
			MX8MP_IOMUXC_SD1_DATA2__GPIO2_IO04	0x00000106	/* DO1 - 36 */
			MX8MP_IOMUXC_SD1_CLK__GPIO2_IO00	0x00000106	/* DI1 - 32 */
			MX8MP_IOMUXC_SD1_DATA3__GPIO2_IO05	0x00000106	/* DO2 - 37 */
			MX8MP_IOMUXC_SD1_CMD__GPIO2_IO01	0x00000106	/* DI2 - 33 */
			MX8MP_IOMUXC_SD1_DATA4__GPIO2_IO06	0x00000106	/* DO3 - 38 */
			MX8MP_IOMUXC_SD1_DATA0__GPIO2_IO02	0x00000106	/* DI3 - 34 */
			MX8MP_IOMUXC_SD1_DATA5__GPIO2_IO07	0x00000106	/* DO4 - 39 */
			MX8MP_IOMUXC_SD1_DATA1__GPIO2_IO03	0x00000106	/* DI4 - 35 */
		>;
	};
};

&vpu_g1 {
	status = "okay";
};

&vpu_g2 {
	status = "okay";
};

&vpu_vc8000e {
	status = "okay";
};

&gpu_3d {
	status = "okay";
};

&gpu_2d {
	status = "okay";
};

&ml_vipsi {
	status = "okay";
};

&mix_gpu_ml {
	status = "okay";
};

&mipi_csi_0 {
        #address-cells = <1>;
        #size-cells = <0>;
	status = "okay";

        port@0 {
		reg = <0>;
                mipi_csi0_ep: endpoint {
                        remote-endpoint = <&ov4689_mipi_0_ep>;
                        data-lanes = <4>;
                        csis-hs-settle = <22>;
                        csis-clk-settle = <3>;
                        csis-wclk;
                };
        };
};

&mipi_csi_1 {
        #address-cells = <1>;
        #size-cells = <0>;
        status = "okay";

        port@1 {
		reg = <1>;
                mipi_csi1_ep: endpoint {
                        remote-endpoint = <&ov4689_mipi_1_ep>;
                        data-lanes = <4>;
                        csis-hs-settle = <22>;
                        csis-clk-settle = <3>;
                        csis-wclk;
                };
        };
};

&cameradev {
        status = "okay";
};

&isi_0 {
	status = "okay";

	cap_device {
		status = "okay";
	};

	m2m_device {
		status = "disabled";
	};
};

&isp_0 {
	status = "disabled";

	cap_device {
		status = "okay";
	};
};

&isi_1 {
	status = "okay";

	cap_device {
		status = "okay";
	};
};

&dsp {
	status = "okay";
};

&cpu_alert0 {
	temperature = <105000>;
};

&cpu_crit0 {
	temperature = <105000>;
};

&soc_alert0 {
	temperature = <105000>;
};

&soc_crit0 {
	temperature = <105000>;
};
